# MKL28T7_CORE0 register map
Vendor: Freescale Semiconductor, Inc.; Series: Kinetis_L; File version: 1.6
CPU: CM0PLUS r0p0, little endian, no MPU, no FPU, VTOR, 2 interrupt priority bits
Registers are 32-bit, read-write, reset 0x0 unless marked. A register's access mark holds for its fields unless they carry their own. Offsets are from the block's base; [hi:lo] are bit positions; {n}, {i} and the like mark numbered series.

## LPIT0 — Low Power Periodic Interrupt Timer (LPIT)
Base 0x40030000; register names take the prefix LPIT0_
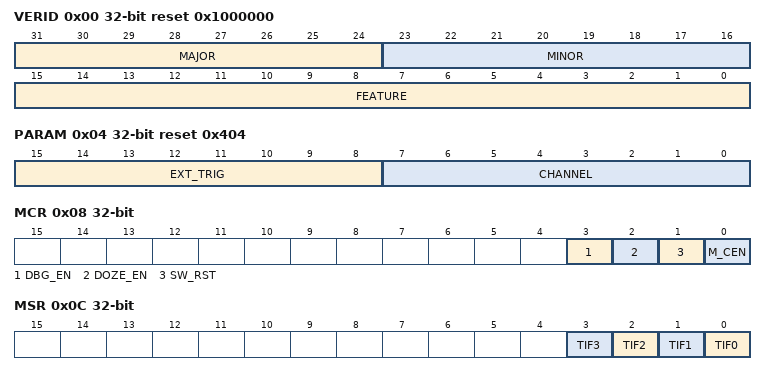
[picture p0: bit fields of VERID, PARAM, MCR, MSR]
0x00 VERID ro reset 0x1000000 — Version ID Register
  [31:24] MAJOR — Major Version Number
  [23:16] MINOR — Minor Version Number
  [15:0] FEATURE — Feature Number
0x04 PARAM ro reset 0x404 — Parameter Register
  [15:8] EXT_TRIG — Number of External Trigger Inputs
  [7:0] CHANNEL — Number of Timer Channels
0x08 MCR — Module Control Register
  [3] DBG_EN — Debug Enable Bit
    0=Timer channels are stopped in Debug mode; 1=Timer channels continue to run in Debug mode
  [2] DOZE_EN — DOZE Mode Enable Bit
    0=Timer channels are stopped in DOZE mode; 1=Timer channels continue to run in DOZE mode
  [1] SW_RST — Software Reset Bit
    0=Timer channels and registers are not reset; 1=Timer channels and registers are reset
  [0] M_CEN — Module Clock Enable
    0=Protocol clock to timers is disabled; 1=Protocol clock to timers is enabled
0x0C MSR — Module Status Register
  [all] fields
    0=Timer has not timed out; 1=Timeout has occurred
  [n] TIF{n} (n=0..3) — Channel {n} Timer Interrupt Flag
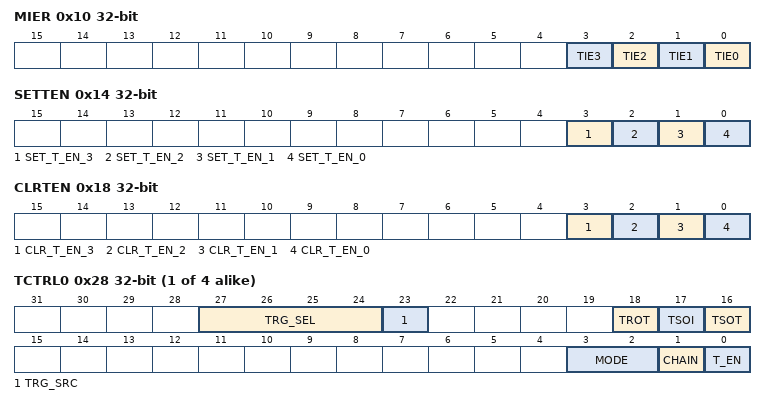
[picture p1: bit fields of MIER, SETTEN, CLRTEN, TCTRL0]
0x10 MIER — Module Interrupt Enable Register
  [all] fields
    0=Interrupt generation is disabled; 1=Interrupt generation is enabled
  [n] TIE{n} (n=0..3) — Channel {n} Timer Interrupt Enable
0x14 SETTEN — Set Timer Enable Register
  [3] SET_T_EN_3 — Set Timer 3 Enable
    0=No effect; 1=Enables the Timer Channel 3
  [2] SET_T_EN_2 — Set Timer 2 Enable
    0=No Effect; 1=Enables the Timer Channel 2
  [1] SET_T_EN_1 — Set Timer 1 Enable
    0=No Effect; 1=Enables the Timer Channel 1
  [0] SET_T_EN_0 — Set Timer 0 Enable
    0=No effect; 1=Enables the Timer Channel 0
0x18 CLRTEN — Clear Timer Enable Register
  [3] CLR_T_EN_3 wo — Clear Timer 3 Enable
    0=No Action; 1=Clear T_EN bit for Timer Channel 3
  [2] CLR_T_EN_2 wo — Clear Timer 2 Enable
    0=No Action; 1=Clear T_EN bit for Timer Channel 2
  [1] CLR_T_EN_1 wo — Clear Timer 1 Enable
    0=No Action; 1=Clear T_EN bit for Timer Channel 1
  [0] CLR_T_EN_0 wo — Clear Timer 0 Enable
    0=No action; 1=Clear T_EN bit for Timer Channel 0
{0x20+0x10*i} TVAL{i} (i=0..3) — Timer Value Register
  [31:0] TMR_VAL — Timer Value
    0=Invalid load value in compare modes
{0x24+0x10*i} CVAL{i} (i=0..3) ro reset 0xFFFFFFFF — Current Timer Value
  [31:0] TMR_CUR_VAL
{0x28+0x10*i} TCTRL{i} (i=0..3) — Timer Control Register
  [27:24] TRG_SEL — Trigger Select
    0=Timer channel 0 trigger source is selected; 1=Timer channel 1 trigger source is selected; 2=Timer channel 2 trigger source is selected
  [23] TRG_SRC — Trigger Source
    0=Trigger source selected in external; 1=Trigger source selected is the internal trigger
  [18] TROT — Timer Reload On Trigger
    0=Timer will not reload on selected trigger; 1=Timer will reload on selected trigger
  [17] TSOI — Timer Stop On Interrupt
    0=Timer does not stop after timeout; 1=Timer will stop after timeout and will restart after rising edge on the T_EN bit is detected (i.e. timer channel is disabled and then enabled)
  [16] TSOT — Timer Start On Trigger
    0=Timer starts to decrement immediately based on restart condition (controlled by TSOI bit); 1=Timer starts to decrement when rising edge on selected trigger is detected
  [3:2] MODE — Timer Operation Mode
    0=32-bit Periodic Counter; 1=Dual 16-bit Periodic Counter; 2=32-bit Trigger Accumulator; 3=32-bit Trigger Input Capture
  [1] CHAIN — Chain Channel
    0=Channel Chaining is disabled. Channel Timer runs independently.; 1=Channel Chaining is enabled. Timer decrements on previous channel's timeout
  [0] T_EN — Timer Enable
    0=Timer Channel is disabled; 1=Timer Channel is enabled

## LPIT1 — Low Power Periodic Interrupt Timer (LPIT)
Base 0x400B1000; register names take the prefix LPIT1_
Registers as LPIT0.
